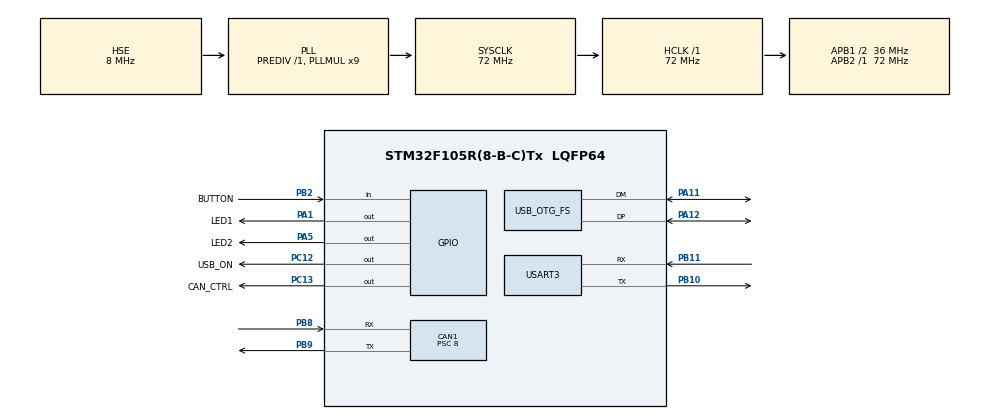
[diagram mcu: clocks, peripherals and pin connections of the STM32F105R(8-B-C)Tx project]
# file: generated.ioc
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CAN1.BS1=CAN_BS1_3TQ
CAN1.BS2=CAN_BS2_5TQ
CAN1.CalculateTimeBit=2000
CAN1.CalculateTimeQuantum=222.22222222222223
CAN1.Mode=CAN_MODE_SILENT_LOOPBACK
CAN1.NART=ENABLE
CAN1.Prescaler=8
CAN1.SJW=CAN_SJW_3TQ
FREERTOS.Queues01=CAN_TO_SERIAL,16,FromDevice,NULL,Dynamic,NULL,NULL;COMMAND_QUEUE,16,ToDevice,NULL,Dynamic,NULL,NULL
FREERTOS.Tasks01=QToCAN,0,128,QToCANF,Default,NULL,Dynamic,NULL,NULL;QToCDC,-3,128,QToCDCF,Default,NULL,Dynamic,NULL,NULL
FREERTOS.configTOTAL_HEAP_SIZE=10000
Mcu.Family=STM32F1
Mcu.Name=STM32F105R(8-B-C)Tx
Mcu.Package=LQFP64
NVIC.CAN1_RX0_IRQn=true\:5\:0\:false\:false\:true\:true
NVIC.CAN1_RX1_IRQn=true\:5\:0\:false\:false\:true\:true
NVIC.CAN1_TX_IRQn=true\:5\:0\:false\:false\:true\:true
NVIC.OTG_FS_IRQn=true\:5\:0\:false\:false\:true\:true
NVIC.PriorityGroup=NVIC_PRIORITYGROUP_4
NVIC.RCC_IRQn=true\:0\:0\:false\:false\:true\:false
NVIC.TIM2_IRQn=true\:0\:0\:false\:false\:true\:false
NVIC.TimeBase=TIM2_IRQn
NVIC.TimeBaseIP=TIM2
NVIC.USART3_IRQn=true\:5\:0\:false\:false\:true\:true
PA1.GPIO_Label=LED1
PA1.Signal=GPIO_Output
PA11.Mode=Device_Only
PA11.Signal=USB_OTG_FS_DM
PA12.Mode=Device_Only
PA12.Signal=USB_OTG_FS_DP
PA13.Mode=Serial_Wire
PA13.Signal=SYS_JTMS-SWDIO
PA14.Mode=Serial_Wire
PA14.Signal=SYS_JTCK-SWCLK
PA5.GPIO_Label=LED2
PA5.Signal=GPIO_Output
PB10.Mode=Asynchronous
PB10.Signal=USART3_TX
PB11.Mode=Asynchronous
PB11.Signal=USART3_RX
PB2.GPIO_Label=BUTTON
PB2.Signal=GPIO_Input
PB8.Mode=Master
PB8.Signal=CAN1_RX
PB9.Mode=Master
PB9.Signal=CAN1_TX
PC12.GPIO_Label=USB_ON
PC12.PinState=GPIO_PIN_RESET
PC12.Signal=GPIO_Output
PC13-TAMPER-RTC.GPIO_Label=CAN_CTRL
PC13-TAMPER-RTC.Signal=GPIO_Output
PD0-OSC_IN.Mode=HSE-External-Oscillator
PD0-OSC_IN.Signal=RCC_OSC_IN
PD1-OSC_OUT.Mode=HSE-External-Oscillator
PD1-OSC_OUT.Signal=RCC_OSC_OUT
ProjectManager.HeapSize=0x200
ProjectManager.StackSize=0x400
ProjectManager.TargetToolchain=MDK-ARM V5
RCC.AHBFreq_Value=72000000
RCC.APB1CLKDivider=RCC_HCLK_DIV2
RCC.APB1Freq_Value=36000000
RCC.APB1TimFreq_Value=72000000
RCC.APB2Freq_Value=72000000
RCC.APB2TimFreq_Value=72000000
RCC.HCLKFreq_Value=72000000
RCC.PLLMUL=RCC_PLL_MUL9
RCC.Prediv2=RCC_HSE_PREDIV2_DIV2
RCC.SYSCLKFreq_VALUE=72000000
RCC.SYSCLKSource=RCC_SYSCLKSOURCE_PLLCLK
RCC.USBFreq_Value=48000000
USART3.VirtualMode=VM_ASYNC
USB_DEVICE.CLASS_NAME_FS=CDC
USB_DEVICE.VirtualMode=Cdc
USB_DEVICE.VirtualModeFS=Cdc_FS
USB_OTG_FS.VirtualMode=Device_Only
VP_FREERTOS_VS_ENABLE.Mode=Enabled
VP_SYS_VS_tim2.Mode=TIM2
VP_USB_DEVICE_VS_USB_DEVICE_CDC_FS.Mode=CDC_FS
board=generated

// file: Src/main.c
/**
  ******************************************************************************
  * File Name          : main.c
  * Description        : Main program body
  ******************************************************************************
  * This notice applies to any and all portions of this file
  * that are not between comment pairs USER CODE BEGIN and
  * USER CODE END. Other portions of this file, whether
  * inserted by the user or by software development tools
  * are owned by their respective copyright owners.
  *
  * Copyright (c) 2017 STMicroelectronics International N.V.
  * All rights reserved.
  *
  * Redistribution and use in source and binary forms, with or without
  * modification, are permitted, provided that the following conditions are met:
  *
  * 1. Redistribution of source code must retain the above copyright notice,
  *    this list of conditions and the following disclaimer.
  * 2. Redistributions in binary form must reproduce the above copyright notice,
  *    this list of conditions and the following disclaimer in the documentation
  *    and/or other materials provided with the distribution.
  * 3. Neither the name of STMicroelectronics nor the names of other
  *    contributors to this software may be used to endorse or promote products
  *    derived from this software without specific written permission.
  * 4. This software, including modifications and/or derivative works of this
  *    software, must execute solely and exclusively on microcontroller or
  *    microprocessor devices manufactured by or for STMicroelectronics.
  * 5. Redistribution and use of this software other than as permitted under
  *    this license is void and will automatically terminate your rights under
  *    this license.
  *
  * THIS SOFTWARE IS PROVIDED BY STMICROELECTRONICS AND CONTRIBUTORS "AS IS"
  * AND ANY EXPRESS, IMPLIED OR STATUTORY WARRANTIES, INCLUDING, BUT NOT
  * LIMITED TO, THE IMPLIED WARRANTIES OF MERCHANTABILITY, FITNESS FOR A
  * PARTICULAR PURPOSE AND NON-INFRINGEMENT OF THIRD PARTY INTELLECTUAL PROPERTY
  * RIGHTS ARE DISCLAIMED TO THE FULLEST EXTENT PERMITTED BY LAW. IN NO EVENT
  * SHALL STMICROELECTRONICS OR CONTRIBUTORS BE LIABLE FOR ANY DIRECT, INDIRECT,
  * INCIDENTAL, SPECIAL, EXEMPLARY, OR CONSEQUENTIAL DAMAGES (INCLUDING, BUT NOT
  * LIMITED TO, PROCUREMENT OF SUBSTITUTE GOODS OR SERVICES; LOSS OF USE, DATA,
  * OR PROFITS; OR BUSINESS INTERRUPTION) HOWEVER CAUSED AND ON ANY THEORY OF
  * LIABILITY, WHETHER IN CONTRACT, STRICT LIABILITY, OR TORT (INCLUDING
  * NEGLIGENCE OR OTHERWISE) ARISING IN ANY WAY OUT OF THE USE OF THIS SOFTWARE,
  * EVEN IF ADVISED OF THE POSSIBILITY OF SUCH DAMAGE.
  *
  ******************************************************************************
  */
#include "main.h"
#include "stm32f1xx_hal.h"
#include "cmsis_os.h"
#include "can.h"
#include "usart.h"
#include "usb_device.h"
#include "gpio.h"

/* USER CODE BEGIN Includes */

#include "main.h"
/* USER CODE END Includes */

/* USER CODE BEGIN PV */
/* Private variables ---------------------------------------------------------*/

/* USER CODE END PV */

void SystemClock_Config(void);
void MX_FREERTOS_Init(void);

/* USER CODE BEGIN PFP */
/* Private function prototypes -----------------------------------------------*/

/* USER CODE END PFP */

int main(void)
{

  /* MCU Configuration----------------------------------------------------------*/

  /* Reset of all peripherals, Initializes the Flash interface and the Systick. */
  HAL_Init();

  /* Configure the system clock */
  SystemClock_Config();

  /* Initialize all configured peripherals */
  MX_GPIO_Init();
  MX_CAN1_Init();
  MX_USART3_UART_Init();

  /* USER CODE BEGIN 2 */
  HAL_CAN_DeInit(&hcan1);
  println("Booted");
  customInit();
  /* USER CODE END 2 */

  /* Call init function for freertos objects (in freertos.c) */
  MX_FREERTOS_Init();

  /* Start scheduler */
  osKernelStart();

  /* We should never get here as control is now taken by the scheduler */

  /* Infinite loop */
  while (1) {

  }

}

/** System Clock Configuration
*/
void SystemClock_Config(void)
{

  RCC_OscInitTypeDef RCC_OscInitStruct;
  RCC_ClkInitTypeDef RCC_ClkInitStruct;
  RCC_PeriphCLKInitTypeDef PeriphClkInit;

    /**Initializes the CPU, AHB and APB busses clocks
    */
  RCC_OscInitStruct.OscillatorType = RCC_OSCILLATORTYPE_HSE;
  RCC_OscInitStruct.HSEState = RCC_HSE_ON;
  RCC_OscInitStruct.HSEPredivValue = RCC_HSE_PREDIV_DIV1;
  RCC_OscInitStruct.HSIState = RCC_HSI_ON;
  RCC_OscInitStruct.Prediv1Source = RCC_PREDIV1_SOURCE_HSE;
  RCC_OscInitStruct.PLL.PLLState = RCC_PLL_ON;
  RCC_OscInitStruct.PLL.PLLSource = RCC_PLLSOURCE_HSE;
  RCC_OscInitStruct.PLL.PLLMUL = RCC_PLL_MUL9;
  RCC_OscInitStruct.PLL2.PLL2State = RCC_PLL_NONE;
  if (HAL_RCC_OscConfig(&RCC_OscInitStruct) != HAL_OK)
  {
    _Error_Handler(__FILE__, __LINE__);
  }

    /**Initializes the CPU, AHB and APB busses clocks
    */
  RCC_ClkInitStruct.ClockType = RCC_CLOCKTYPE_HCLK|RCC_CLOCKTYPE_SYSCLK
                              |RCC_CLOCKTYPE_PCLK1|RCC_CLOCKTYPE_PCLK2;
  RCC_ClkInitStruct.SYSCLKSource = RCC_SYSCLKSOURCE_PLLCLK;
  RCC_ClkInitStruct.AHBCLKDivider = RCC_SYSCLK_DIV1;
  RCC_ClkInitStruct.APB1CLKDivider = RCC_HCLK_DIV2;
  RCC_ClkInitStruct.APB2CLKDivider = RCC_HCLK_DIV1;

  if (HAL_RCC_ClockConfig(&RCC_ClkInitStruct, FLASH_LATENCY_2) != HAL_OK)
  {
    _Error_Handler(__FILE__, __LINE__);
  }

  PeriphClkInit.PeriphClockSelection = RCC_PERIPHCLK_USB;
  PeriphClkInit.UsbClockSelection = RCC_USBCLKSOURCE_PLL_DIV3;
  if (HAL_RCCEx_PeriphCLKConfig(&PeriphClkInit) != HAL_OK)
  {
    _Error_Handler(__FILE__, __LINE__);
  }

    /**Configure the Systick interrupt time
    */
  HAL_SYSTICK_Config(HAL_RCC_GetHCLKFreq()/1000);

    /**Configure the Systick
    */
  HAL_SYSTICK_CLKSourceConfig(SYSTICK_CLKSOURCE_HCLK);

    /**Configure the Systick interrupt time
    */
  __HAL_RCC_PLLI2S_ENABLE();

  /* SysTick_IRQn interrupt configuration */
  HAL_NVIC_SetPriority(SysTick_IRQn, 15, 0);
}

void HAL_TIM_PeriodElapsedCallback(TIM_HandleTypeDef *htim)
{
  if (htim->Instance == TIM2) {
    HAL_IncTick();
  }
}

void _Error_Handler(char * file, int line)
{
  while (1) {
  }
}

/************************ (C) COPYRIGHT STMicroelectronics *****END OF FILE****/

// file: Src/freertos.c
/**
  ******************************************************************************
  * File Name          : freertos.c
  * Description        : Code for freertos applications
  ******************************************************************************
  * This notice applies to any and all portions of this file
  * that are not between comment pairs USER CODE BEGIN and
  * USER CODE END. Other portions of this file, whether
  * inserted by the user or by software development tools
  * are owned by their respective copyright owners.
  *
  * Copyright (c) 2017 STMicroelectronics International N.V.
  * All rights reserved.
  *
  * Redistribution and use in source and binary forms, with or without
  * modification, are permitted, provided that the following conditions are met:
  *
  * 1. Redistribution of source code must retain the above copyright notice,
  *    this list of conditions and the following disclaimer.
  * 2. Redistributions in binary form must reproduce the above copyright notice,
  *    this list of conditions and the following disclaimer in the documentation
  *    and/or other materials provided with the distribution.
  * 3. Neither the name of STMicroelectronics nor the names of other
  *    contributors to this software may be used to endorse or promote products
  *    derived from this software without specific written permission.
  * 4. This software, including modifications and/or derivative works of this
  *    software, must execute solely and exclusively on microcontroller or
  *    microprocessor devices manufactured by or for STMicroelectronics.
  * 5. Redistribution and use of this software other than as permitted under
  *    this license is void and will automatically terminate your rights under
  *    this license.
  *
  * THIS SOFTWARE IS PROVIDED BY STMICROELECTRONICS AND CONTRIBUTORS "AS IS"
  * AND ANY EXPRESS, IMPLIED OR STATUTORY WARRANTIES, INCLUDING, BUT NOT
  * LIMITED TO, THE IMPLIED WARRANTIES OF MERCHANTABILITY, FITNESS FOR A
  * PARTICULAR PURPOSE AND NON-INFRINGEMENT OF THIRD PARTY INTELLECTUAL PROPERTY
  * RIGHTS ARE DISCLAIMED TO THE FULLEST EXTENT PERMITTED BY LAW. IN NO EVENT
  * SHALL STMICROELECTRONICS OR CONTRIBUTORS BE LIABLE FOR ANY DIRECT, INDIRECT,
  * INCIDENTAL, SPECIAL, EXEMPLARY, OR CONSEQUENTIAL DAMAGES (INCLUDING, BUT NOT
  * LIMITED TO, PROCUREMENT OF SUBSTITUTE GOODS OR SERVICES; LOSS OF USE, DATA,
  * OR PROFITS; OR BUSINESS INTERRUPTION) HOWEVER CAUSED AND ON ANY THEORY OF
  * LIABILITY, WHETHER IN CONTRACT, STRICT LIABILITY, OR TORT (INCLUDING
  * NEGLIGENCE OR OTHERWISE) ARISING IN ANY WAY OUT OF THE USE OF THIS SOFTWARE,
  * EVEN IF ADVISED OF THE POSSIBILITY OF SUCH DAMAGE.
  *
  ******************************************************************************
  */

#include "FreeRTOS.h"
#include "task.h"
#include "cmsis_os.h"

/* USER CODE BEGIN Includes */
#include "custom.h"
#include "messages.pb-c.h"
/* USER CODE END Includes */

osThreadId QToCANHandle;
osThreadId QToCDCHandle;
osMessageQId CAN_TO_SERIALHandle;
osMessageQId COMMAND_QUEUEHandle;

void QToCANF(void const * argument);
void QToCDCF(void const * argument);

extern void MX_USB_DEVICE_Init(void);
void MX_FREERTOS_Init(void); /* (MISRA C 2004 rule 8.1) */

/* Hook prototypes */

/* Init FreeRTOS */

void MX_FREERTOS_Init(void) {

  /* Create the thread(s) */
  /* definition and creation of QToCAN */
  osThreadDef(QToCAN, QToCANF, osPriorityNormal, 0, 128);
  QToCANHandle = osThreadCreate(osThread(QToCAN), NULL);

  /* definition and creation of QToCDC */
  osThreadDef(QToCDC, QToCDCF, osPriorityIdle, 0, 128);
  QToCDCHandle = osThreadCreate(osThread(QToCDC), NULL);

  /* Create the queue(s) */
  /* definition and creation of CAN_TO_SERIAL */
  osMessageQDef(CAN_TO_SERIAL, 16, FromDevice);
  CAN_TO_SERIALHandle = osMessageCreate(osMessageQ(CAN_TO_SERIAL), NULL);

  /* definition and creation of COMMAND_QUEUE */
  osMessageQDef(COMMAND_QUEUE, 16, ToDevice);
  COMMAND_QUEUEHandle = osMessageCreate(osMessageQ(COMMAND_QUEUE), NULL);

}

/* QToCANF function */
void QToCANF(void const * argument)
{
  /* init code for USB_DEVICE */
  MX_USB_DEVICE_Init();

  /* USER CODE BEGIN QToCANF */
  CommandQueueProcess(argument);
  /* Infinite loop */
  /* USER CODE END QToCANF */
}

/* QToCDCF function */
void QToCDCF(void const * argument)
{
  /* USER CODE BEGIN QToCDCF */
  /* Infinite loop */
  QueueToUsb(argument);
  /* USER CODE END QToCDCF */
}

/************************ (C) COPYRIGHT STMicroelectronics *****END OF FILE****/
